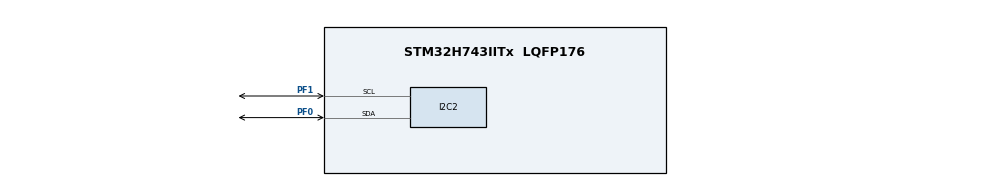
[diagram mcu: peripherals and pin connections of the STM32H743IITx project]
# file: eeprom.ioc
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CORTEX_M7.default_mode_Activation=1
I2C2.DualAddressMode=I2C_DUALADDRESS_ENABLE
I2C2.GeneralCallMode=I2C_GENERALCALL_DISABLE
I2C2.OwnAddress=10
I2C2.Timing=0x307075B1
Mcu.Family=STM32H7
Mcu.Name=STM32H743IITx
Mcu.Package=LQFP176
NVIC.PriorityGroup=NVIC_PRIORITYGROUP_4
PF0.Mode=I2C
PF0.Signal=I2C2_SDA
PF1.Mode=I2C
PF1.Signal=I2C2_SCL
PH0-OSC_IN\ (PH0).Mode=HSE-External-Clock-Source
PH0-OSC_IN\ (PH0).Signal=RCC_OSC_IN
ProjectManager.HeapSize=0x200
ProjectManager.StackSize=0x400
ProjectManager.TargetToolchain=MDK-ARM V5.27
RCC.ADCFreq_Value=32250000
RCC.APB1Freq_Value=120000000
RCC.APB2Freq_Value=120000000
RCC.APB3Freq_Value=120000000
RCC.APB4Freq_Value=120000000
RCC.CortexFreq_Value=480000000
RCC.D1PPRE=RCC_APB3_DIV2
RCC.D2PPRE1=RCC_APB1_DIV2
RCC.D2PPRE2=RCC_APB2_DIV2
RCC.D3PPRE=RCC_APB4_DIV2
RCC.DIVM1=1
RCC.DIVN1=60
RCC.HCLKFreq_Value=240000000
RCC.HPRE=RCC_HCLK_DIV2
RCC.HSE_VALUE=16000000
RCC.PLLFRACN=0
RCC.PLLSourceVirtual=RCC_PLLSOURCE_HSE
RCC.SYSCLKFreq_VALUE=480000000
RCC.SYSCLKSource=RCC_SYSCLKSOURCE_PLLCLK
RCC.USBFreq_Value=480000000
board=custom

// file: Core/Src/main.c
/* USER CODE BEGIN Header */
/**
  ******************************************************************************
  * @file           : main.c
  * @brief          : Main program body
  ******************************************************************************
  * @attention
  *
  * Copyright (c) 2024 STMicroelectronics.
  * All rights reserved.
  *
  * This software is licensed under terms that can be found in the LICENSE file
  * in the root directory of this software component.
  * If no LICENSE file comes with this software, it is provided AS-IS.
  *
  ******************************************************************************
  */
/* USER CODE END Header */
#include "main.h"

/* USER CODE BEGIN Includes */
#include "string.h"

#define EEPROM_ADDRESS 0xA0
/* USER CODE END Includes */

void SystemClock_Config(void);
static void MPU_Config(void);
static void MX_GPIO_Init(void);
static void MX_I2C2_Init(void);
/* USER CODE BEGIN PFP */
uint8_t EEPROM_WriteArray(uint16_t memAddress, uint8_t *data, uint16_t size);
uint8_t EEPROM_ReadArray(uint16_t memAddress, uint8_t *data, uint16_t size);
/* USER CODE END PFP */

/* USER CODE BEGIN 0 */
uint8_t writeData[16];
uint8_t readData[16];
char flag_write=0;
char flag_read=0;
char err_write=0;
char err_read=0;
float data1=15.65,ret1=0;
float data2=85.32,ret2=0;
float data3=0.025,ret3=0;
/* USER CODE END 0 */

int main(void)
{

  /* MPU Configuration--------------------------------------------------------*/
  MPU_Config();

  /* MCU Configuration--------------------------------------------------------*/

  /* Reset of all peripherals, Initializes the Flash interface and the Systick. */
  LL_APB4_GRP1_EnableClock(LL_APB4_GRP1_PERIPH_SYSCFG);

  /* System interrupt init*/
  NVIC_SetPriorityGrouping(NVIC_PRIORITYGROUP_4);

  /* SysTick_IRQn interrupt configuration */
  NVIC_SetPriority(SysTick_IRQn, NVIC_EncodePriority(NVIC_GetPriorityGrouping(),15, 0));

  /* Configure the system clock */
  SystemClock_Config();

  /* Initialize all configured peripherals */
  MX_GPIO_Init();
  MX_I2C2_Init();

  /* Infinite loop */
  /* USER CODE BEGIN WHILE */
  while (1)
  {
		if(flag_write)
		{
			memcpy(writeData,&data1,4);
			memcpy(writeData+4,&data2,4);
			memcpy(writeData+8,&data3,4);
			err_write=EEPROM_WriteArray(0x0000, writeData, 12);
			flag_write=0;
		}

		if(flag_read)
		{
			err_read=EEPROM_ReadArray(0x0000, readData, 12);
			memcpy(&ret1,readData,4);
			memcpy(&ret2,readData+4,4);
			memcpy(&ret3,readData+8,4);
			flag_read=0;
		}

    /* USER CODE END WHILE */

    /* USER CODE BEGIN 3 */
  }
}

uint8_t EEPROM_WriteArray(uint16_t memAddress, uint8_t *data, uint16_t size)
{
    uint8_t buffer[size + 2];

    buffer[0] = (uint8_t)(memAddress >> 8);
    buffer[1] = (uint8_t)(memAddress & 0xFF);

    memcpy(&buffer[2], data, size);

    // ????? ???? ?? EEPROM
    LL_I2C_HandleTransfer(I2C2, EEPROM_ADDRESS, LL_I2C_ADDRSLAVE_7BIT, size + 2, LL_I2C_MODE_AUTOEND, LL_I2C_GENERATE_START_WRITE);

    for (uint16_t i = 0; i < size + 2; i++)
    {
        while (!LL_I2C_IsActiveFlag_TXE(I2C2));
        LL_I2C_TransmitData8(I2C2, buffer[i]);
    }

    while (!LL_I2C_IsActiveFlag_STOP(I2C2));
    LL_I2C_ClearFlag_STOP(I2C2);

    return 0;
}

uint8_t EEPROM_ReadArray(uint16_t memAddress, uint8_t *data, uint16_t size)
{
    uint8_t memAddressBuffer[2];

    memAddressBuffer[0] = (uint8_t)(memAddress >> 8);
    memAddressBuffer[1] = (uint8_t)(memAddress & 0xFF);

    LL_I2C_HandleTransfer(I2C2, EEPROM_ADDRESS, LL_I2C_ADDRSLAVE_7BIT, 2, LL_I2C_MODE_SOFTEND, LL_I2C_GENERATE_START_WRITE);

    for (uint8_t i = 0; i < 2; i++)
    {
        while (!LL_I2C_IsActiveFlag_TXE(I2C2));
        LL_I2C_TransmitData8(I2C2, memAddressBuffer[i]);
    }

    while (!LL_I2C_IsActiveFlag_TC(I2C2));

    LL_I2C_HandleTransfer(I2C2, EEPROM_ADDRESS, LL_I2C_ADDRSLAVE_7BIT, size, LL_I2C_MODE_AUTOEND, LL_I2C_GENERATE_START_READ);

    for (uint16_t i = 0; i < size; i++)
    {
        while (!LL_I2C_IsActiveFlag_RXNE(I2C2));
        data[i] = LL_I2C_ReceiveData8(I2C2);
    }

    while (!LL_I2C_IsActiveFlag_STOP(I2C2));
    LL_I2C_ClearFlag_STOP(I2C2);

    return 0;
}

  /* USER CODE END 3 */

void SystemClock_Config(void)
{
  LL_FLASH_SetLatency(LL_FLASH_LATENCY_4);
  while(LL_FLASH_GetLatency()!= LL_FLASH_LATENCY_4)
  {
  }
  LL_PWR_ConfigSupply(LL_PWR_LDO_SUPPLY);
  LL_PWR_SetRegulVoltageScaling(LL_PWR_REGU_VOLTAGE_SCALE0);
  LL_RCC_HSE_EnableBypass();
  LL_RCC_HSE_Enable();

   /* Wait till HSE is ready */
  while(LL_RCC_HSE_IsReady() != 1)
  {

  }
  LL_RCC_PLL_SetSource(LL_RCC_PLLSOURCE_HSE);
  LL_RCC_PLL1P_Enable();
  LL_RCC_PLL1_SetVCOInputRange(LL_RCC_PLLINPUTRANGE_8_16);
  LL_RCC_PLL1_SetVCOOutputRange(LL_RCC_PLLVCORANGE_WIDE);
  LL_RCC_PLL1_SetM(1);
  LL_RCC_PLL1_SetN(60);
  LL_RCC_PLL1_SetP(2);
  LL_RCC_PLL1_SetQ(2);
  LL_RCC_PLL1_SetR(2);
  LL_RCC_PLL1_Enable();

   /* Wait till PLL is ready */
  while(LL_RCC_PLL1_IsReady() != 1)
  {
  }

   /* Intermediate AHB prescaler 2 when target frequency clock is higher than 80 MHz */
   LL_RCC_SetAHBPrescaler(LL_RCC_AHB_DIV_2);

  LL_RCC_SetSysClkSource(LL_RCC_SYS_CLKSOURCE_PLL1);

   /* Wait till System clock is ready */
  while(LL_RCC_GetSysClkSource() != LL_RCC_SYS_CLKSOURCE_STATUS_PLL1)
  {

  }
  LL_RCC_SetSysPrescaler(LL_RCC_SYSCLK_DIV_1);
  LL_RCC_SetAHBPrescaler(LL_RCC_AHB_DIV_2);
  LL_RCC_SetAPB1Prescaler(LL_RCC_APB1_DIV_2);
  LL_RCC_SetAPB2Prescaler(LL_RCC_APB2_DIV_2);
  LL_RCC_SetAPB3Prescaler(LL_RCC_APB3_DIV_2);
  LL_RCC_SetAPB4Prescaler(LL_RCC_APB4_DIV_2);

  LL_Init1msTick(480000000);

  LL_SetSystemCoreClock(480000000);
}

static void MX_I2C2_Init(void)
{

  LL_I2C_InitTypeDef I2C_InitStruct = {0};

  LL_GPIO_InitTypeDef GPIO_InitStruct = {0};

  LL_RCC_SetI2CClockSource(LL_RCC_I2C123_CLKSOURCE_PCLK1);

  LL_AHB4_GRP1_EnableClock(LL_AHB4_GRP1_PERIPH_GPIOF);
  /**I2C2 GPIO Configuration
  PF0   ------> I2C2_SDA
  PF1   ------> I2C2_SCL
  */
  GPIO_InitStruct.Pin = LL_GPIO_PIN_0|LL_GPIO_PIN_1;
  GPIO_InitStruct.Mode = LL_GPIO_MODE_ALTERNATE;
  GPIO_InitStruct.Speed = LL_GPIO_SPEED_FREQ_LOW;
  GPIO_InitStruct.OutputType = LL_GPIO_OUTPUT_OPENDRAIN;
  GPIO_InitStruct.Pull = LL_GPIO_PULL_NO;
  GPIO_InitStruct.Alternate = LL_GPIO_AF_4;
  LL_GPIO_Init(GPIOF, &GPIO_InitStruct);

  /* Peripheral clock enable */
  LL_APB1_GRP1_EnableClock(LL_APB1_GRP1_PERIPH_I2C2);

  /** I2C Initialization
  */
  LL_I2C_EnableAutoEndMode(I2C2);
  LL_I2C_SetOwnAddress2(I2C2, 0, LL_I2C_OWNADDRESS2_NOMASK);
  LL_I2C_EnableOwnAddress2(I2C2);
  LL_I2C_DisableGeneralCall(I2C2);
  LL_I2C_EnableClockStretching(I2C2);
  I2C_InitStruct.PeripheralMode = LL_I2C_MODE_I2C;
  I2C_InitStruct.Timing = 0x307075B1;
  I2C_InitStruct.AnalogFilter = LL_I2C_ANALOGFILTER_ENABLE;
  I2C_InitStruct.DigitalFilter = 0;
  I2C_InitStruct.OwnAddress1 = 20;
  I2C_InitStruct.TypeAcknowledge = LL_I2C_ACK;
  I2C_InitStruct.OwnAddrSize = LL_I2C_OWNADDRESS1_7BIT;
  LL_I2C_Init(I2C2, &I2C_InitStruct);

}

static void MX_GPIO_Init(void)
{

  /* GPIO Ports Clock Enable */
  LL_AHB4_GRP1_EnableClock(LL_AHB4_GRP1_PERIPH_GPIOF);
  LL_AHB4_GRP1_EnableClock(LL_AHB4_GRP1_PERIPH_GPIOH);

}

/* MPU Configuration */

void MPU_Config(void)
{

  /* Disables the MPU */
  LL_MPU_Disable();
  /* Enables the MPU */
  LL_MPU_Enable(LL_MPU_CTRL_PRIVILEGED_DEFAULT);

}

void Error_Handler(void)
{
  __disable_irq();
  while (1)
  {
  }
}
